# S32K312_M7 register map
Vendor: NXP Semiconductors; File version: 1.4
CPU: CM7 r0p1, little endian, MPU, FPU, VTOR, 4 interrupt priority bits
Registers are 32-bit, read-write, reset 0x0 unless marked. A register's access mark holds for its fields unless they carry their own. Offsets are from the block's base; [hi:lo] are bit positions; {n}, {i} and the like mark numbered series; 'fields as' and 'values as' point back to an identical list.

## TEMPSENSE
Base 0x4037C000
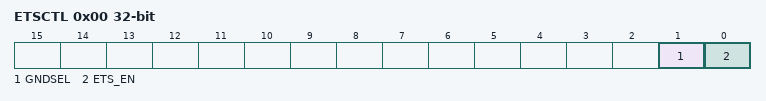
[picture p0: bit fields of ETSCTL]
0x00 ETSCTL — ETS Control
  [1] GNDSEL — Ground selection
    0=No exposure of the ground; 1=Expose ground on the ADC output if ETS_EN=1
  [0] ETS_EN — Temperature Sensor enable
    0=Power down; 1=Functional mode
{0x8+4i} TCA{i} ro reset not defined (i=0..2) — Temperature Coefficient
  [15:0] TCA{i} — Temperature coefficient A{i}

## CRC
Base 0x40380000
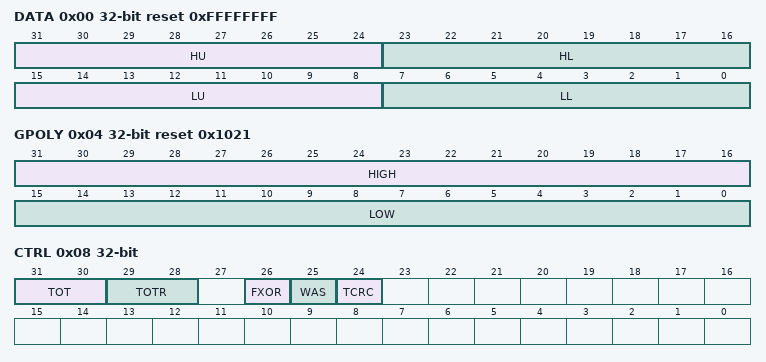
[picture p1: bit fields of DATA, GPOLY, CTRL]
0x00 DATA reset 0xFFFFFFFF — CRC DATA register
  [31:24] HU — CRC High Upper Byte
  [23:16] HL — CRC High Lower Byte
  [15:8] LU — CRC Low Upper Byte
  [7:0] LL — CRC Low Lower Byte
0x04 GPOLY reset 0x1021 — CRC Polynomial register
  [31:16] HIGH — High Polynominal Half-word
  [15:0] LOW — Low Polynominal Half-word
0x08 CTRL — CRC Control register
  [31:30] TOT — Type Of Transpose For Writes
    0=No transposition; 1=Bits in bytes are transposed; bytes are not transposed; 2=Both bits in bytes and bytes are transposed; 3=Only bytes are transposed; no bits in a byte are transposed
  [29:28] TOTR — Type Of Transpose For Read
    values as TOT
  [26] FXOR — Complement Read Of CRC DATA register
    0=No XOR on reading; 1=Invert or complement the read value of the CRC DATA register
  [25] WAS — Write CRC DATA register As Seed
    0=Writes to the CRC DATA register are data values; 1=Writes to the CRC DATA register are seed values
  [24] TCRC
    0=16-bit CRC protocol; 1=32-bit CRC protocol

## JDC
Base 0x40394000
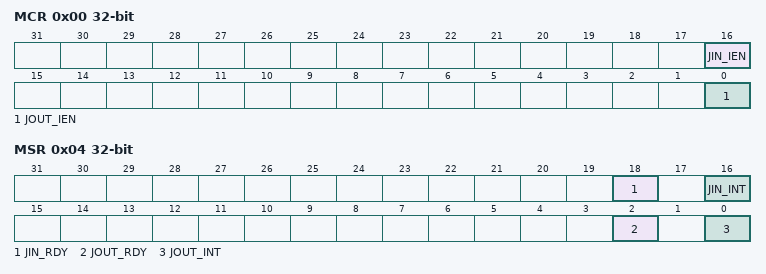
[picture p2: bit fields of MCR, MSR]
0x00 MCR — Module Configuration Register
  [16] JIN_IEN — JIN Interrupt Enable.
    0=Setting MSR[JIN_INT] bit does not assert the JIN interrupt; 1=Setting MSR[JIN_INT] bit asserts the JIN interrupt
  [0] JOUT_IEN — JOUT Interrupt Enable.
    0=Setting MSR[JOUT_INT] bit does not assert the JOUT interrupt; 1=Setting MSR[JOUT_INT] bit asserts the JOUT interrupt
0x04 MSR — Module Status Register
  [18] JIN_RDY ro — JIN Ready (read only).
    0=Cleared upon software read of JIN_IPS contents via IPS; 1=Set when new data is written to the JIN_IPS register
  [16] JIN_INT write-1-clears — JIN Interrupt.
    0=Cleared by writing logic 1; 1=Set when new data is written to the JIN_IPS register
  [2] JOUT_RDY ro — JOUT Ready (read only).
    0=Cleared upon tool read of JOUT register via JTAG port; 1=Set when new data is written to the JOUT_IPS register
  [0] JOUT_INT write-1-clears — JOUT Interrupt.
    0=Cleared by writing logic 1; 1=Set when JOUT_RDY bit is cleared by tool reading JOUT register
0x08 JOUT_IPS — JTAG Output Data Register
  [31:0] Data — JOUT_IPS data.
0x0C JIN_IPS ro — JTAG Input Data Register
  [31:0] Data — JIN_IPS data.

## CONFIGURATION_GPR
Base 0x4039C000
0x1C CONFIG_REG0 ro — General Purpose Configuration 0
  [6] EDB — Hardware Debugger Attached
    0=Debugger not connected; 1=Debugger connected
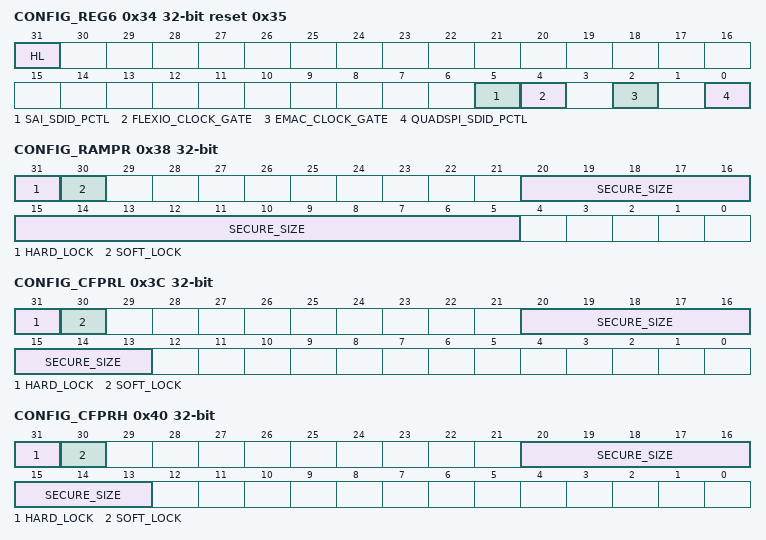
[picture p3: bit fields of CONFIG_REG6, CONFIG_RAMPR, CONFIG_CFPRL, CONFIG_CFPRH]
0x34 CONFIG_REG6 ro reset 0x35 — General Purpose Configuration 6
  [31] HL — Hard Lock
    0=You can write to this register; 1=Register is locked for any write
  [5] SAI_SDID_PCTL — SAI0 and SAI1 clock gating
    0=Clock is off (gated); 1=Clock is on
  [4] FLEXIO_CLOCK_GATE — FlexIO Clock Gating
    0=Clock is off (gated); 1=Clock is on
  [2] EMAC_CLOCK_GATE — Ethernet Clock Gating
    0=Clock is off (gated); 1=Clock is on
  [0] QUADSPI_SDID_PCTL — QuadSPI Clock Gating
    0=Clock is off (gated); 1=Clock is on
0x38 CONFIG_RAMPR ro reset not defined — Configuration RAM Protected Region
  [31] HARD_LOCK
    0=Write access is allowed; 1=Write access is not allowed until next functional reset
  [30] SOFT_LOCK
    0=Write access is allowed; 1=Write access is not allowed
  [20:5] SECURE_SIZE
0x3C CONFIG_CFPRL ro reset not defined — Configuration Code Flash Memory Active Block
  [31] HARD_LOCK
    values as CONFIG_RAMPR.HARD_LOCK
  [30] SOFT_LOCK
    0=Write access is allowed; 1=Write access is not allowed
  [20:13] SECURE_SIZE
0x40 CONFIG_CFPRH ro reset not defined — Configuration Code Flash Memory Passive Block
  fields as CONFIG_CFPRL
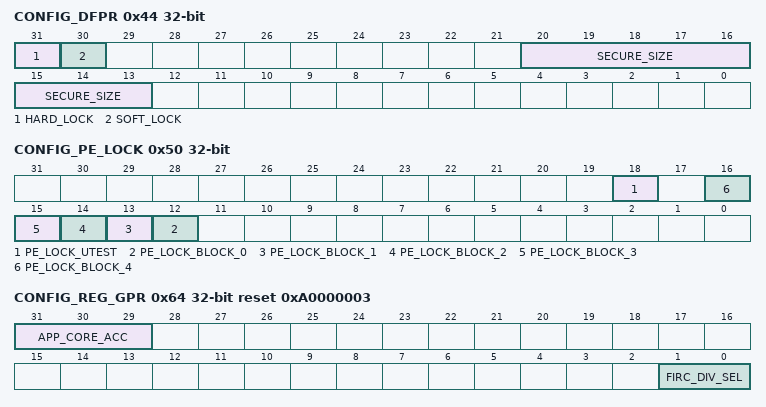
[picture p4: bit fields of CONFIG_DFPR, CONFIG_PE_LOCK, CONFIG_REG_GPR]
0x44 CONFIG_DFPR ro reset not defined — Configuration Data Flash Memory Protected Region
  fields as CONFIG_CFPRL
0x50 CONFIG_PE_LOCK ro — Configuration Program and Erase Lock
  [18] PE_LOCK_UTEST — Program/Erase Lock for UTEST
    0=UTEST lock request is clear; 1=UTEST lock requested
  [n+12] PE_LOCK_BLOCK_{n} (n=0..4) — Program/Erase Lock for Block {n}
    0=Block {n} lock request is clear; 1=Block {n} lock requested
0x54 CONFIG_RAMPR_ALT ro reset not defined — Configuration RAM Protected Region Alternate
  [31:0] INVERT_VALUE_RAMPR
0x58 CONFIG_CFPRL_ALT ro reset not defined — Configuration Code Flash Memory Active Block Alternate
  [31:0] INVERT_VALUE_CFPRAB
0x5C CONFIG_CFPRH_ALT ro reset not defined — Configuration Code Flash Memory Passive Block Alternate
  [31:0] INVERT_VALUE_CFPRP
0x60 CONFIG_DFPR_ALT ro reset not defined — Configuration Data Flash Memory Protected Region Alternate
  [31:0] INVERT_VALUE_DFPR — Invert Value CFPRP
0x64 CONFIG_REG_GPR reset 0xA0000003 — Configuration REG_GPR
  [31:29] APP_CORE_ACC ro — FIRC Divider
    5=Application core can write this field [FIRC_DIV_SEL]
  [1:0] FIRC_DIV_SEL — FIRC Divider
    0=Divided by 2; 1=Divided by 2; 2=Divided by 16; 3=Undivided

## MCM_0_CM7 — MCM
Base 0xE0080000
0x00 PLREV 16-bit ro — SoC-defined Platform Revision
  [15:0] PLREV — The PLREV[15:0] field is specified by a platform input signal to define a software-visible revision number.
0x02 PCT 16-bit ro reset 0xAC70 — Processor Core Type
  [15:0] PCT — This MCM design supports the Arm Cortex M7 core. The following value identifies this core complex.
    0xAC70=Arm Cortex M7
0x0C CPCR reset 0x200 — Core Platform Control
  [27] CM7_AHBSPRI — AHB Slave Priority
    0=Uses a round-robin arbitration scheme; 1=AHB-slave access has priority over a core access
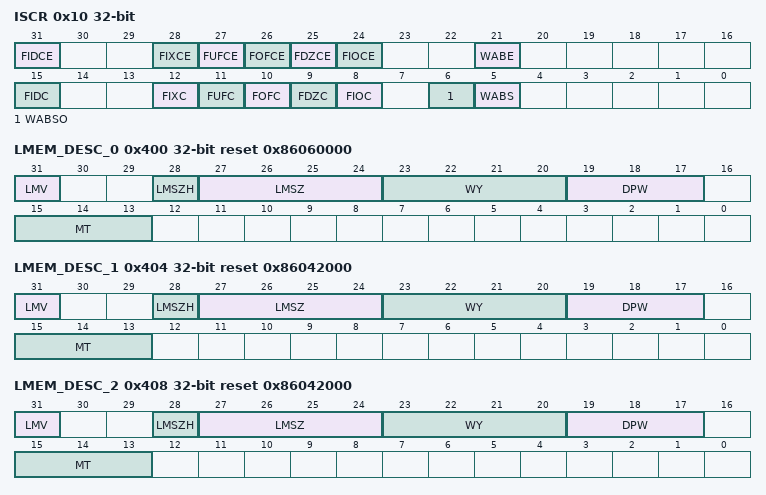
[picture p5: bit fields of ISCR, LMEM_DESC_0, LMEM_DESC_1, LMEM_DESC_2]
0x10 ISCR — Interrupt Status and Control
  [31] FIDCE — FPU Input Denormal Interrupt Enable
    0=Disable interrupt; 1=Enable interrupt
  [28] FIXCE — FPU Inexact Interrupt Enable
    0=Disable interrupt; 1=Enable interrupt
  [27] FUFCE — FPU Underflow Interrupt Enable
    0=Disable interrupt; 1=Enable interrupt
  [26] FOFCE — FPU Overflow Interrupt Enable
    0=Disable interrupt; 1=Enable interrupt
  [25] FDZCE — FPU Divide-by-Zero Interrupt Enable
    0=Disable interrupt; 1=Enable interrupt
  [24] FIOCE — FPU Invalid Operation Interrupt Enable
    0=Disable interrupt; 1=Enable interrupt
  [21] WABE — TCM Write Abort Interrupt Enable
    0=Disable interrupt; 1=Enable Interrupt
  [15] FIDC ro — FPU Input Denormal Interrupt Status
    0=No interrupt; 1=Interrupt occurred
  [12] FIXC ro — FPU Inexact Interrupt Status
    0=No interrupt; 1=Interrupt occurred
  [11] FUFC ro — FPU Underflow Interrupt Status
    0=No interrupt; 1=Interrupt occurred
  [10] FOFC ro — FPU Overflow Interrupt Status
    0=No interrupt; 1=Interrupt occurred
  [9] FDZC ro — FPU Divide-by-Zero Interrupt Status
    0=No interrupt; 1=Interrupt occurred
  [8] FIOC ro — FPU Invalid Operation Interrupt Status
    0=No interrupt; 1=Interrupt occurred
  [6] WABSO ro — Write Abort on Slave Overrun
    0=No write abort overrun; 1=Write abort overrun occurred
  [5] WABS write-1-clears — Write Abort on Slave
    0=No write abort occurred on AHBS interface; 1=Write abort occurred on AHBS interface
0x400 LMEM_DESC_0 reset 0x86060000 — Local Memory Descriptor 0
  [31] LMV ro — Local Memory Valid
    0=NOT_PRESENT (LMEMn not present); 1=PRESENT (LMEMn present)
  [28] LMSZH ro — LMEM Size Hole
    0=PWR_OF_2 (LMEMn is a power-of-2 capacity); 1=NOT_PWR_OF_2 (LMEMn is not a power-of-2, with capacity of 0.75 x LMSZ)
  [27:24] LMSZ ro — Local Memory Size
    0=0 KB; 1=1 KB; 2=2 KB; 3=4 KB; 4=8 KB; 5=16 KB; 6=32 KB; 7=64 KB; 8=128 KB; 9=256 KB; 10=512 KB; 11=1024 KB; 12=2048 KB; 13=4096 KB; 14=8192 KB; 15=16384 KB
  [23:20] WY ro — Level 1 Cache Ways
    0=No cache; 2=2-way set associative; 4=4-way set associative
  [19:17] DPW ro — Data Path Width
    2=WIDE_32 (LMEMn is 32-bits wide); 3=WIDE_64 (LMEMn is 64-bits wide)
  [15:13] MT ro — Memory Type
    0=ITCM; 1=DTCM; 2=ICACHE; 3=DCACHE
0x404 LMEM_DESC_1 reset 0x86042000 — Local Memory Descriptor 1
  fields as LMEM_DESC_0
0x408 LMEM_DESC_2 reset 0x86042000 — Local Memory Descriptor 2
  fields as LMEM_DESC_0
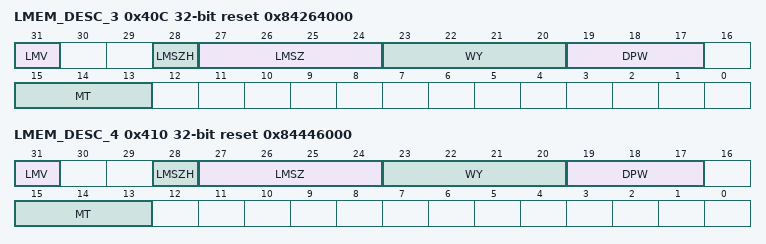
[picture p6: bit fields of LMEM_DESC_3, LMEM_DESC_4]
0x40C LMEM_DESC_3 reset 0x84264000 — Local Memory Descriptor 3
  fields as LMEM_DESC_0
0x410 LMEM_DESC_4 reset 0x84446000 — Local Memory Descriptor 4
  fields as LMEM_DESC_0
